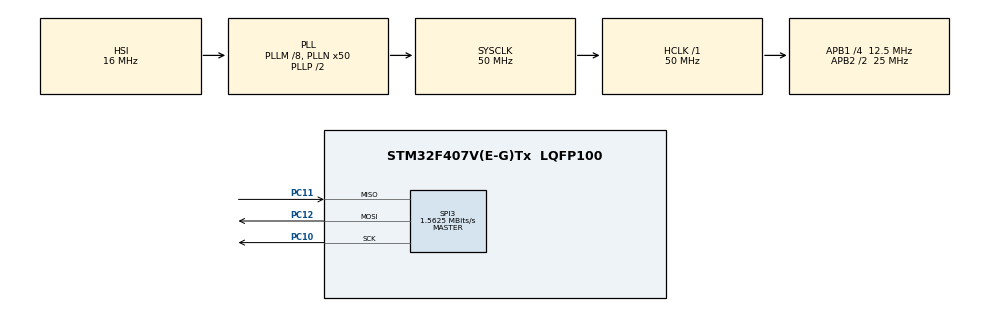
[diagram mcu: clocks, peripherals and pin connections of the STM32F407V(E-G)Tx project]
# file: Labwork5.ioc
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Mcu.Family=STM32F4
Mcu.Name=STM32F407V(E-G)Tx
Mcu.Package=LQFP100
NVIC.PriorityGroup=NVIC_PRIORITYGROUP_0
PC10.Mode=Full_Duplex_Master
PC10.Signal=SPI3_SCK
PC11.Mode=Full_Duplex_Master
PC11.Signal=SPI3_MISO
PC12.Mode=Full_Duplex_Master
PC12.Signal=SPI3_MOSI
ProjectManager.HeapSize=0x200
ProjectManager.StackSize=0x400
ProjectManager.TargetToolchain=STM32CubeIDE
RCC.48MHZClocksFreq_Value=14285714.285714285
RCC.AHBFreq_Value=50000000
RCC.APB1CLKDivider=RCC_HCLK_DIV4
RCC.APB1Freq_Value=12500000
RCC.APB1TimFreq_Value=25000000
RCC.APB2CLKDivider=RCC_HCLK_DIV2
RCC.APB2Freq_Value=25000000
RCC.APB2TimFreq_Value=50000000
RCC.CortexFreq_Value=50000000
RCC.HCLKFreq_Value=50000000
RCC.HSE_VALUE=8000000
RCC.HSI_VALUE=16000000
RCC.PLLM=8
RCC.PLLN=50
RCC.PLLQ=7
RCC.SYSCLKFreq_VALUE=50000000
RCC.SYSCLKSource=RCC_SYSCLKSOURCE_PLLCLK
RCC.VCOOutputFreq_Value=100000000
SPI3.BaudRatePrescaler=SPI_BAUDRATEPRESCALER_8
SPI3.CalculateBaudRate=1.5625 MBits/s
SPI3.Direction=SPI_DIRECTION_2LINES
SPI3.Mode=SPI_MODE_MASTER
SPI3.VirtualType=VM_MASTER
board=STM32F407G-DISC1

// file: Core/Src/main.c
/* USER CODE BEGIN Header */
/**
  ******************************************************************************
  * @file           : main.c
  * @brief          : Main program body
  ******************************************************************************
  * @attention
  *
  * Copyright (c) 2023 STMicroelectronics.
  * All rights reserved.
  *
  * This software is licensed under terms that can be found in the LICENSE file
  * in the root directory of this software component.
  * If no LICENSE file comes with this software, it is provided AS-IS.
  *
  ******************************************************************************
  */
/* USER CODE END Header */
#include "main.h"

SPI_HandleTypeDef hspi3;

/* USER CODE BEGIN PV */
uint8_t TxBuffer[]= {4, 5, 7, 12};
uint8_t RxBuffer[4];

/* USER CODE END PV */

void SystemClock_Config(void);
static void MX_GPIO_Init(void);
static void MX_SPI3_Init(void);

int main(void)
{

  /* MCU Configuration--------------------------------------------------------*/

  /* Reset of all peripherals, Initializes the Flash interface and the Systick. */
  HAL_Init();

  /* Configure the system clock */
  SystemClock_Config();

  /* Initialize all configured peripherals */
  MX_GPIO_Init();
  MX_SPI3_Init();
  /* USER CODE BEGIN 2 */
  HAL_SPI_TransmitReceive(&hspi3, TxBuffer, RxBuffer, 4,100);
  /* USER CODE END 2 */

  /* Infinite loop */
  while (1)
  {

  }
}

void SystemClock_Config(void)
{
  RCC_OscInitTypeDef RCC_OscInitStruct = {0};
  RCC_ClkInitTypeDef RCC_ClkInitStruct = {0};

  /** Configure the main internal regulator output voltage
  */
  __HAL_RCC_PWR_CLK_ENABLE();
  __HAL_PWR_VOLTAGESCALING_CONFIG(PWR_REGULATOR_VOLTAGE_SCALE1);

  /** Initializes the RCC Oscillators according to the specified parameters
  * in the RCC_OscInitTypeDef structure.
  */
  RCC_OscInitStruct.OscillatorType = RCC_OSCILLATORTYPE_HSI;
  RCC_OscInitStruct.HSIState = RCC_HSI_ON;
  RCC_OscInitStruct.HSICalibrationValue = RCC_HSICALIBRATION_DEFAULT;
  RCC_OscInitStruct.PLL.PLLState = RCC_PLL_ON;
  RCC_OscInitStruct.PLL.PLLSource = RCC_PLLSOURCE_HSI;
  RCC_OscInitStruct.PLL.PLLM = 8;
  RCC_OscInitStruct.PLL.PLLN = 50;
  RCC_OscInitStruct.PLL.PLLP = RCC_PLLP_DIV2;
  RCC_OscInitStruct.PLL.PLLQ = 7;
  if (HAL_RCC_OscConfig(&RCC_OscInitStruct) != HAL_OK)
  {
    Error_Handler();
  }

  /** Initializes the CPU, AHB and APB buses clocks
  */
  RCC_ClkInitStruct.ClockType = RCC_CLOCKTYPE_HCLK|RCC_CLOCKTYPE_SYSCLK
                              |RCC_CLOCKTYPE_PCLK1|RCC_CLOCKTYPE_PCLK2;
  RCC_ClkInitStruct.SYSCLKSource = RCC_SYSCLKSOURCE_PLLCLK;
  RCC_ClkInitStruct.AHBCLKDivider = RCC_SYSCLK_DIV1;
  RCC_ClkInitStruct.APB1CLKDivider = RCC_HCLK_DIV4;
  RCC_ClkInitStruct.APB2CLKDivider = RCC_HCLK_DIV2;

  if (HAL_RCC_ClockConfig(&RCC_ClkInitStruct, FLASH_LATENCY_1) != HAL_OK)
  {
    Error_Handler();
  }
}

static void MX_SPI3_Init(void)
{

  /* SPI3 parameter configuration*/
  hspi3.Instance = SPI3;
  hspi3.Init.Mode = SPI_MODE_MASTER;
  hspi3.Init.Direction = SPI_DIRECTION_2LINES;
  hspi3.Init.DataSize = SPI_DATASIZE_8BIT;
  hspi3.Init.CLKPolarity = SPI_POLARITY_LOW;
  hspi3.Init.CLKPhase = SPI_PHASE_1EDGE;
  hspi3.Init.NSS = SPI_NSS_SOFT;
  hspi3.Init.BaudRatePrescaler = SPI_BAUDRATEPRESCALER_8;
  hspi3.Init.FirstBit = SPI_FIRSTBIT_MSB;
  hspi3.Init.TIMode = SPI_TIMODE_DISABLE;
  hspi3.Init.CRCCalculation = SPI_CRCCALCULATION_DISABLE;
  hspi3.Init.CRCPolynomial = 10;
  if (HAL_SPI_Init(&hspi3) != HAL_OK)
  {
    Error_Handler();
  }

}

static void MX_GPIO_Init(void)
{

  /* GPIO Ports Clock Enable */
  __HAL_RCC_GPIOC_CLK_ENABLE();

}

void Error_Handler(void)
{
  __disable_irq();
  while (1)
  {
  }
}
